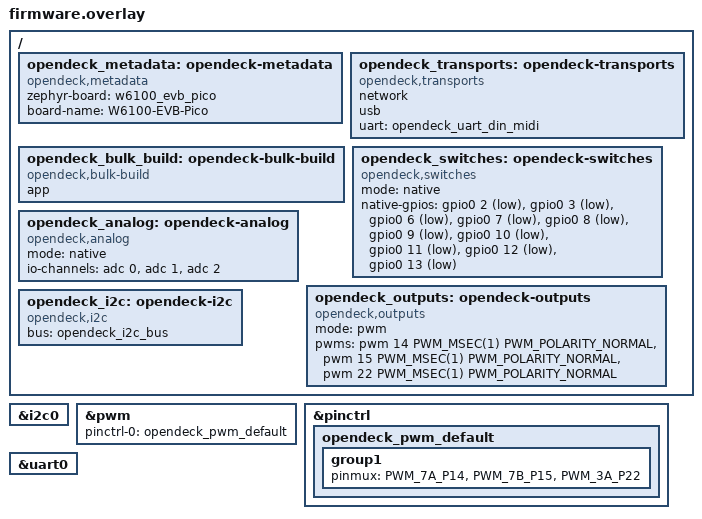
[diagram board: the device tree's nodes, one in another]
#include <zephyr/dt-bindings/pwm/pwm.h>
#include <zephyr/dt-bindings/pinctrl/rpi-pico-pinctrl-common.h>

/ {
    opendeck_metadata: opendeck-metadata {
        compatible = "opendeck,metadata";
        zephyr-board = "w6100_evb_pico";
        board-name = "W6100-EVB-Pico";
    };

    opendeck_transports: opendeck-transports {
        compatible = "opendeck,transports";
        network;
        usb;
        uart = <&opendeck_uart_din_midi>;
    };

    opendeck_bulk_build: opendeck-bulk-build {
        compatible = "opendeck,bulk-build";
        app;
    };

    opendeck_switches: opendeck-switches {
        compatible = "opendeck,switches";
        mode = "native";
        native-gpios =
            <&gpio0 2 (GPIO_PULL_UP | GPIO_ACTIVE_LOW)>,
            <&gpio0 3 (GPIO_PULL_UP | GPIO_ACTIVE_LOW)>,
            <&gpio0 6 (GPIO_PULL_UP | GPIO_ACTIVE_LOW)>,
            <&gpio0 7 (GPIO_PULL_UP | GPIO_ACTIVE_LOW)>,
            <&gpio0 8 (GPIO_PULL_UP | GPIO_ACTIVE_LOW)>,
            <&gpio0 9 (GPIO_PULL_UP | GPIO_ACTIVE_LOW)>,
            <&gpio0 10 (GPIO_PULL_UP | GPIO_ACTIVE_LOW)>,
            <&gpio0 11 (GPIO_PULL_UP | GPIO_ACTIVE_LOW)>,
            <&gpio0 12 (GPIO_PULL_UP | GPIO_ACTIVE_LOW)>,
            <&gpio0 13 (GPIO_PULL_UP | GPIO_ACTIVE_LOW)>;
    };

    opendeck_analog: opendeck-analog {
        compatible = "opendeck,analog";
        mode = "native";
        io-channels =
            <&adc 0>, /* GP26 */
            <&adc 1>, /* GP27 */
            <&adc 2>; /* GP28 */
    };

    opendeck_outputs: opendeck-outputs {
        compatible = "opendeck,outputs";
        mode = "pwm";
        pwms =
            <&pwm 14 PWM_MSEC(1) PWM_POLARITY_NORMAL>,
            <&pwm 15 PWM_MSEC(1) PWM_POLARITY_NORMAL>,
            <&pwm 22 PWM_MSEC(1) PWM_POLARITY_NORMAL>;
    };

    opendeck_i2c: opendeck-i2c {
        compatible = "opendeck,i2c";
        bus = <&opendeck_i2c_bus>;
    };
};

&i2c0 {
    status = "okay";
};

&pwm {
    pinctrl-0 = <&opendeck_pwm_default>;
    pinctrl-names = "default";
    status = "okay";
};

&pinctrl {
    opendeck_pwm_default: opendeck_pwm_default {
        group1 {
            pinmux = <PWM_7A_P14>,
                     <PWM_7B_P15>,
                     <PWM_3A_P22>;
        };
    };
};

&uart0 {
    status = "okay";
};
